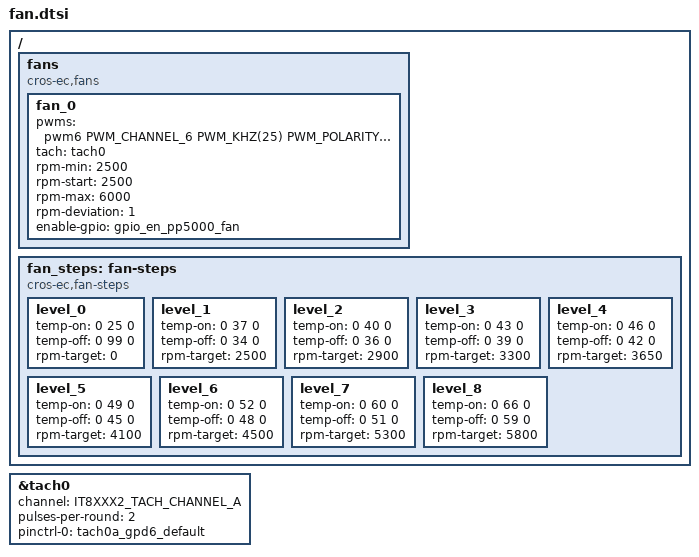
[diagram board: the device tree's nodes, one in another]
/* Copyright 2026 The ChromiumOS Authors
 * Use of this source code is governed by a BSD-style license that can be
 * found in the LICENSE file.
 */
/ {
	fans {
		compatible = "cros-ec,fans";
		fan_0 {
			pwms = <&pwm6 PWM_CHANNEL_6
				PWM_KHZ(25)
				PWM_POLARITY_NORMAL>;
			tach = <&tach0>;
			rpm-min = <2500>;
			rpm-start = <2500>;
			rpm-max = <6000>;
			rpm-deviation = <1>;
			enable-gpio = <&gpio_en_pp5000_fan>;
		};
	};

	fan_steps: fan-steps {
		compatible = "cros-ec,fan-steps";
		level_0 {
			temp-on = <0 25 0>;
			temp-off = <0 99 0>;
			rpm-target = <0>;
		};
		level_1 {
			temp-on = <0 37 0>;
			temp-off = <0 34 0>;
			rpm-target = <2500>;
		};
		level_2 {
			temp-on = <0 40 0>;
			temp-off = <0 36 0>;
			rpm-target = <2900>;
		};
		level_3 {
			temp-on = <0 43 0>;
			temp-off = <0 39 0>;
			rpm-target = <3300>;
		};
		level_4 {
			temp-on = <0 46 0>;
			temp-off = <0 42 0>;
			rpm-target = <3650>;
		};
		level_5 {
			temp-on = <0 49 0>;
			temp-off = <0 45 0>;
			rpm-target = <4100>;
		};
		level_6 {
			temp-on = <0 52 0>;
			temp-off = <0 48 0>;
			rpm-target = <4500>;
		};
		level_7 {
			temp-on = <0 60 0>;
			temp-off = <0 51 0>;
			rpm-target = <5300>;
		};
		level_8 {
			temp-on = <0 66 0>;
			temp-off = <0 59 0>;
			rpm-target = <5800>;
		};
	};
};

/* fan tachometer sensor */
&tach0 {
	status = "okay";
	channel = <IT8XXX2_TACH_CHANNEL_A>;
	pulses-per-round = <2>;
	pinctrl-0 = <&tach0a_gpd6_default>;
	pinctrl-names = "default";
};
